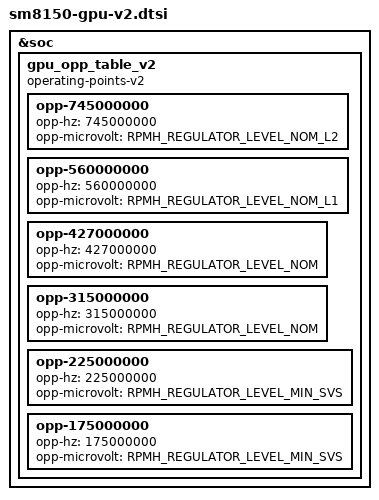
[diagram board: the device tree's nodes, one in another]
/* Copyright (c) 2018-2019, The Linux Foundation. All rights reserved.
 *
 * This program is free software; you can redistribute it and/or modify
 * it under the terms of the GNU General Public License version 2 and
 * only version 2 as published by the Free Software Foundation.
 *
 * This program is distributed in the hope that it will be useful,
 * but WITHOUT ANY WARRANTY; without even the implied warranty of
 * MERCHANTABILITY or FITNESS FOR A PARTICULAR PURPOSE.  See the
 * GNU General Public License for more details.
 */

&soc {
	gpu_opp_table_v2: gpu_opp_table_v2 {
		compatible = "operating-points-v2";

		opp-745000000 {
			opp-hz = /bits/ 64 <745000000>;
			opp-microvolt = <RPMH_REGULATOR_LEVEL_NOM_L2>;
		};

		opp-560000000 {
			opp-hz = /bits/ 64 <560000000>;
			opp-microvolt = <RPMH_REGULATOR_LEVEL_NOM_L1>;
		};

		opp-427000000 {
			opp-hz = /bits/ 64 <427000000>;
			opp-microvolt = <RPMH_REGULATOR_LEVEL_NOM>;
		};

		opp-315000000 {
			opp-hz = /bits/ 64 <315000000>;
			opp-microvolt = <RPMH_REGULATOR_LEVEL_NOM>;
		};

		opp-225000000 {
			opp-hz = /bits/ 64 <225000000>;
			opp-microvolt = <RPMH_REGULATOR_LEVEL_MIN_SVS>;
		};

		opp-175000000 {
			opp-hz = /bits/ 64 <175000000>;
			opp-microvolt = <RPMH_REGULATOR_LEVEL_MIN_SVS>;
		};
	};
};
